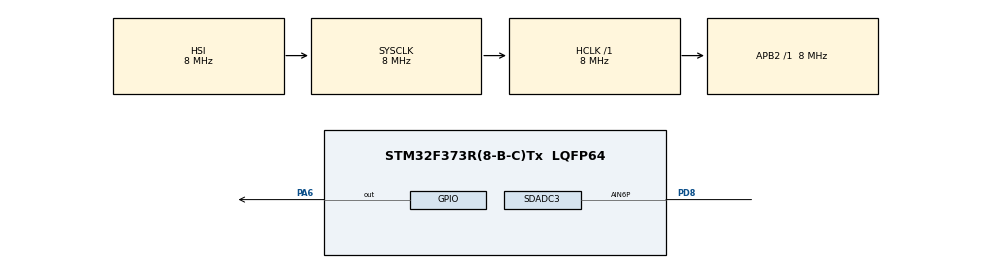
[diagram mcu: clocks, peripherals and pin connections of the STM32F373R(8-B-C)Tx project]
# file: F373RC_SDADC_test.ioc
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Mcu.Family=STM32F3
Mcu.Name=STM32F373R(8-B-C)Tx
Mcu.Package=LQFP64
NVIC.PriorityGroup=NVIC_PRIORITYGROUP_4
PA13.Mode=Serial_Wire
PA13.Signal=SYS_JTMS-SWDIO
PA14.Mode=Serial_Wire
PA14.Signal=SYS_JTCK-SWCLK
PA6.Signal=GPIO_Output
PD8.Mode=IN6-Single-Ended
PD8.Signal=SDADC3_AIN6P
ProjectManager.HeapSize=0x200
ProjectManager.StackSize=0x400
ProjectManager.TargetToolchain=STM32CubeIDE
RCC.AHBFreq_Value=8000000
RCC.APB2Freq_Value=8000000
RCC.CortexFreq_Value=8000000
RCC.HSE_VALUE=8000000
RCC.HSI_VALUE=8000000
RCC.LSE_VALUE=32768
RCC.SYSCLKFreq_VALUE=8000000
SDADC3.NbrOfConversionFlag=1
SDADC3.ReferenceVoltage=SDADC_VREF_VDDA
VP_SDADC3_CONF0.Mode=ConfigZero
board=custom

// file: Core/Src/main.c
/* USER CODE BEGIN Header */
/**
  ******************************************************************************
  * @file           : main.c
  * @brief          : Main program body
  ******************************************************************************
  * @attention
  *
  * <h2><center>&copy; Copyright (c) 2020 STMicroelectronics.
  * All rights reserved.</center></h2>
  *
  * This software component is licensed by ST under BSD 3-Clause license,
  * the "License"; You may not use this file except in compliance with the
  * License. You may obtain a copy of the License at:
  *                        opensource.org/licenses/BSD-3-Clause
  *
  ******************************************************************************
  */
/* USER CODE END Header */
#include "main.h"

SDADC_HandleTypeDef hsdadc3;

/* USER CODE BEGIN PV */
uint16_t V_batt;
/* USER CODE END PV */

void SystemClock_Config(void);
static void MX_GPIO_Init(void);
static void MX_SDADC3_Init(void);

int main(void)
{

  /* MCU Configuration--------------------------------------------------------*/

  /* Reset of all peripherals, Initializes the Flash interface and the Systick. */
  HAL_Init();

  /* Configure the system clock */
  SystemClock_Config();

  /* Initialize all configured peripherals */
  MX_GPIO_Init();
  MX_SDADC3_Init();

  /* Infinite loop */
  /* USER CODE BEGIN WHILE */
  while (1)
  {
	  HAL_GPIO_WritePin(GPIOA, GPIO_PIN_10, GPIO_PIN_SET);

	  HAL_SDADC_Start(&hsdadc3);
	  HAL_SDADC_PollForConversion(&hsdadc3, 100);
	  V_batt = HAL_SDADC_GetValue(&hsdadc3);

	  HAL_Delay(500);

    /* USER CODE END WHILE */

  }
}

void SystemClock_Config(void)
{
  RCC_OscInitTypeDef RCC_OscInitStruct = {0};
  RCC_ClkInitTypeDef RCC_ClkInitStruct = {0};
  RCC_PeriphCLKInitTypeDef PeriphClkInit = {0};

  /** Initializes the RCC Oscillators according to the specified parameters
  * in the RCC_OscInitTypeDef structure.
  */
  RCC_OscInitStruct.OscillatorType = RCC_OSCILLATORTYPE_HSI;
  RCC_OscInitStruct.HSIState = RCC_HSI_ON;
  RCC_OscInitStruct.HSICalibrationValue = RCC_HSICALIBRATION_DEFAULT;
  RCC_OscInitStruct.PLL.PLLState = RCC_PLL_NONE;
  if (HAL_RCC_OscConfig(&RCC_OscInitStruct) != HAL_OK)
  {
    Error_Handler();
  }
  /** Initializes the CPU, AHB and APB buses clocks
  */
  RCC_ClkInitStruct.ClockType = RCC_CLOCKTYPE_HCLK|RCC_CLOCKTYPE_SYSCLK
                              |RCC_CLOCKTYPE_PCLK1|RCC_CLOCKTYPE_PCLK2;
  RCC_ClkInitStruct.SYSCLKSource = RCC_SYSCLKSOURCE_HSI;
  RCC_ClkInitStruct.AHBCLKDivider = RCC_SYSCLK_DIV1;
  RCC_ClkInitStruct.APB1CLKDivider = RCC_HCLK_DIV1;
  RCC_ClkInitStruct.APB2CLKDivider = RCC_HCLK_DIV1;

  if (HAL_RCC_ClockConfig(&RCC_ClkInitStruct, FLASH_LATENCY_0) != HAL_OK)
  {
    Error_Handler();
  }
  PeriphClkInit.PeriphClockSelection = RCC_PERIPHCLK_SDADC;
  PeriphClkInit.SdadcClockSelection = RCC_SDADCSYSCLK_DIV2;
  if (HAL_RCCEx_PeriphCLKConfig(&PeriphClkInit) != HAL_OK)
  {
    Error_Handler();
  }
  HAL_PWREx_EnableSDADC(PWR_SDADC_ANALOG3);
}

static void MX_SDADC3_Init(void)
{

  SDADC_ConfParamTypeDef ConfParamStruct = {0};

  /** Configure the SDADC low power mode, fast conversion mode,
  slow clock mode and SDADC1 reference voltage
  */
  hsdadc3.Instance = SDADC3;
  hsdadc3.Init.IdleLowPowerMode = SDADC_LOWPOWER_NONE;
  hsdadc3.Init.FastConversionMode = SDADC_FAST_CONV_DISABLE;
  hsdadc3.Init.SlowClockMode = SDADC_SLOW_CLOCK_DISABLE;
  hsdadc3.Init.ReferenceVoltage = SDADC_VREF_VDDA;
  if (HAL_SDADC_Init(&hsdadc3) != HAL_OK)
  {
    Error_Handler();
  }
  /** Set parameters for SDADC configuration 0 Register
  */
  ConfParamStruct.InputMode = SDADC_INPUT_MODE_DIFF;
  ConfParamStruct.Gain = SDADC_GAIN_1;
  ConfParamStruct.CommonMode = SDADC_COMMON_MODE_VSSA;
  ConfParamStruct.Offset = 0;
  if (HAL_SDADC_PrepareChannelConfig(&hsdadc3, SDADC_CONF_INDEX_0, &ConfParamStruct) != HAL_OK)
  {
    Error_Handler();
  }

}

static void MX_GPIO_Init(void)
{
  GPIO_InitTypeDef GPIO_InitStruct = {0};

  /* GPIO Ports Clock Enable */
  __HAL_RCC_GPIOA_CLK_ENABLE();
  __HAL_RCC_GPIOD_CLK_ENABLE();

  /*Configure GPIO pin Output Level */
  HAL_GPIO_WritePin(GPIOA, GPIO_PIN_6, GPIO_PIN_RESET);

  /*Configure GPIO pin : PA6 */
  GPIO_InitStruct.Pin = GPIO_PIN_6;
  GPIO_InitStruct.Mode = GPIO_MODE_OUTPUT_PP;
  GPIO_InitStruct.Pull = GPIO_NOPULL;
  GPIO_InitStruct.Speed = GPIO_SPEED_FREQ_LOW;
  HAL_GPIO_Init(GPIOA, &GPIO_InitStruct);

}

void Error_Handler(void)
{
  __disable_irq();
  while (1)
  {
  }
}

/************************ (C) COPYRIGHT STMicroelectronics *****END OF FILE****/
